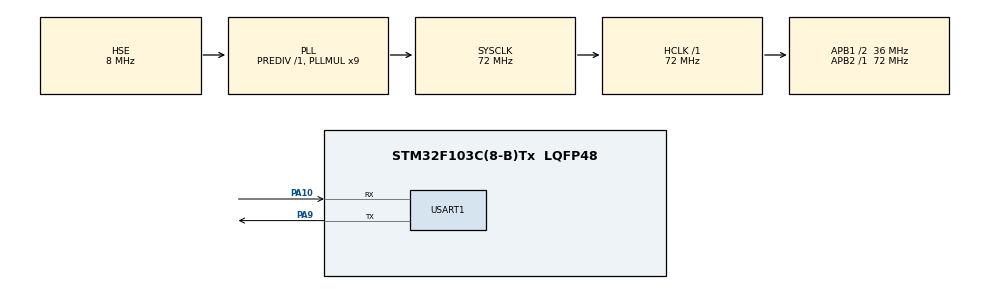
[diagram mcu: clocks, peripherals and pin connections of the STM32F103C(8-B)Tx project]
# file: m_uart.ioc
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Mcu.Family=STM32F1
Mcu.Name=STM32F103C(8-B)Tx
Mcu.Package=LQFP48
NVIC.PriorityGroup=NVIC_PRIORITYGROUP_4
NVIC.USART1_IRQn=true\:2\:0\:true\:false\:true\:true\:true
PA10.Mode=Asynchronous
PA10.Signal=USART1_RX
PA13.Mode=Serial_Wire
PA13.Signal=SYS_JTMS-SWDIO
PA14.Mode=Serial_Wire
PA14.Signal=SYS_JTCK-SWCLK
PA9.Mode=Asynchronous
PA9.Signal=USART1_TX
PD0-OSC_IN.Mode=HSE-External-Oscillator
PD0-OSC_IN.Signal=RCC_OSC_IN
PD1-OSC_OUT.Mode=HSE-External-Oscillator
PD1-OSC_OUT.Signal=RCC_OSC_OUT
ProjectManager.HeapSize=0x200
ProjectManager.StackSize=0x400
ProjectManager.TargetToolchain=MDK-ARM V5
RCC.AHBFreq_Value=72000000
RCC.APB1CLKDivider=RCC_HCLK_DIV2
RCC.APB1Freq_Value=36000000
RCC.APB1TimFreq_Value=72000000
RCC.APB2Freq_Value=72000000
RCC.APB2TimFreq_Value=72000000
RCC.HCLKFreq_Value=72000000
RCC.PLLMUL=RCC_PLL_MUL9
RCC.PLLSourceVirtual=RCC_PLLSOURCE_HSE
RCC.SYSCLKFreq_VALUE=72000000
RCC.SYSCLKSource=RCC_SYSCLKSOURCE_PLLCLK
RCC.USBFreq_Value=72000000
USART1.VirtualMode=VM_ASYNC
board=custom

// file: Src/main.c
/* USER CODE BEGIN Header */
/**
  ******************************************************************************
  * @file           : main.c
  * @brief          : Main program body
  ******************************************************************************
  * @attention
  *
  * <h2><center>&copy; Copyright (c) 2020 STMicroelectronics.
  * All rights reserved.</center></h2>
  *
  * This software component is licensed by ST under BSD 3-Clause license,
  * the "License"; You may not use this file except in compliance with the
  * License. You may obtain a copy of the License at:
  *                        opensource.org/licenses/BSD-3-Clause
  *
  ******************************************************************************
  */

  /**
*  @Author 	: 江山
*  @github 	：(jianggogogo)
*  @notice 	: This code is open to learing and discuss.
*/

/* USER CODE END Header */

#include "main.h"
#include "usart.h"
#include "gpio.h"

void SystemClock_Config(void);
/* USER CODE BEGIN PFP */

#define UART0_PRINTF
#if 1
#pragma import(__use_no_semihosting)
//标准库需要的支持函数
struct __FILE
{
	int handle;

};
FILE __stdout;
//重定义fputc函数
#ifdef __cplusplus
extern "C" {
#endif
int fputc(int ch, FILE *f)
{
	# ifdef UART0_PRINTF
    HAL_UART_Transmit(&huart1, (uint8_t *)&ch,1, 0xFFFF);
	#endif
    return ch;
}
#ifdef __cplusplus
}
#endif

#endif
/* USER CODE END PFP */

/* USER CODE BEGIN 0 */

//串口1中断服务程序
//注意,读取USARTx->SR能避免莫名其妙的错误
uint8_t USART_RX_BUF[256];     //接收缓冲,最大USART_REC_LEN个字节.
//接收状态
//bit15，	接收完成标志
//bit14，	接收到0x0d
//bit13~0，	接收到的有效字节数目
uint16_t USART_RX_STA=0;       //接收状态标记

uint8_t aRxBuffer[256];//HAL库使用的串口接收缓冲

/* USER CODE END 0 */

int main(void)
{

  /* MCU Configuration--------------------------------------------------------*/

  /* Reset of all peripherals, Initializes the Flash interface and the Systick. */
  HAL_Init();

  /* Configure the system clock */
  SystemClock_Config();

  /* Initialize all configured peripherals */
  MX_GPIO_Init();
  MX_USART1_UART_Init();
  /* USER CODE BEGIN 2 */
  	HAL_UART_Receive_IT(&huart1,USART_RX_BUF,1);
  /* USER CODE END 2 */

  /* Infinite loop */
  while (1)
  {
  }
}

void SystemClock_Config(void)
{
  RCC_OscInitTypeDef RCC_OscInitStruct = {0};
  RCC_ClkInitTypeDef RCC_ClkInitStruct = {0};

  /** Initializes the CPU, AHB and APB busses clocks
  */
  RCC_OscInitStruct.OscillatorType = RCC_OSCILLATORTYPE_HSE;
  RCC_OscInitStruct.HSEState = RCC_HSE_ON;
  RCC_OscInitStruct.HSEPredivValue = RCC_HSE_PREDIV_DIV1;
  RCC_OscInitStruct.HSIState = RCC_HSI_ON;
  RCC_OscInitStruct.PLL.PLLState = RCC_PLL_ON;
  RCC_OscInitStruct.PLL.PLLSource = RCC_PLLSOURCE_HSE;
  RCC_OscInitStruct.PLL.PLLMUL = RCC_PLL_MUL9;
  if (HAL_RCC_OscConfig(&RCC_OscInitStruct) != HAL_OK)
  {
    Error_Handler();
  }
  /** Initializes the CPU, AHB and APB busses clocks
  */
  RCC_ClkInitStruct.ClockType = RCC_CLOCKTYPE_HCLK|RCC_CLOCKTYPE_SYSCLK
                              |RCC_CLOCKTYPE_PCLK1|RCC_CLOCKTYPE_PCLK2;
  RCC_ClkInitStruct.SYSCLKSource = RCC_SYSCLKSOURCE_PLLCLK;
  RCC_ClkInitStruct.AHBCLKDivider = RCC_SYSCLK_DIV1;
  RCC_ClkInitStruct.APB1CLKDivider = RCC_HCLK_DIV2;
  RCC_ClkInitStruct.APB2CLKDivider = RCC_HCLK_DIV1;

  if (HAL_RCC_ClockConfig(&RCC_ClkInitStruct, FLASH_LATENCY_2) != HAL_OK)
  {
    Error_Handler();
  }
}

void Error_Handler(void)
{
}

/************************ (C) COPYRIGHT STMicroelectronics *****END OF FILE****/
